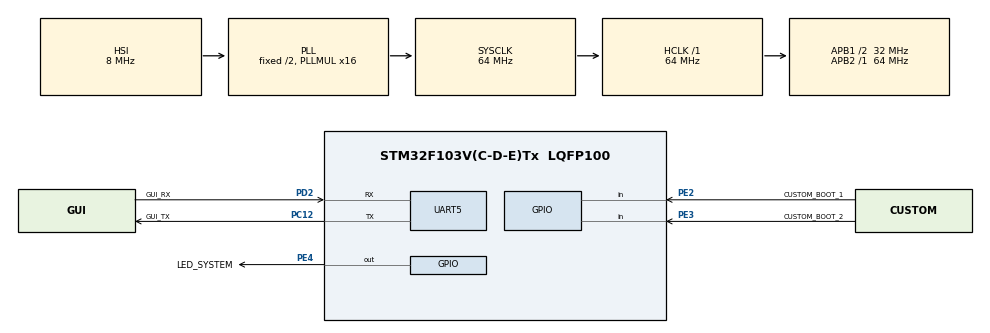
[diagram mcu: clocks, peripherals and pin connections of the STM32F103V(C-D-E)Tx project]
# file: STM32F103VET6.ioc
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Mcu.Family=STM32F1
Mcu.Name=STM32F103V(C-D-E)Tx
Mcu.Package=LQFP100
NVIC.PriorityGroup=NVIC_PRIORITYGROUP_4
NVIC.UART5_IRQn=true\:0\:0\:false\:false\:true\:true\:true\:true
PA13.Mode=JTAG_5_pins
PA13.Signal=SYS_JTMS-SWDIO
PA14.Mode=JTAG_5_pins
PA14.Signal=SYS_JTCK-SWCLK
PA15.Mode=JTAG_5_pins
PA15.Signal=SYS_JTDI
PB3.Mode=JTAG_5_pins
PB3.Signal=SYS_JTDO-TRACESWO
PB4.Mode=JTAG_5_pins
PB4.Signal=SYS_NJTRST
PC12.GPIO_Label=GUI_TX
PC12.Mode=Asynchronous
PC12.Signal=UART5_TX
PD2.GPIO_Label=GUI_RX
PD2.Mode=Asynchronous
PD2.Signal=UART5_RX
PE2.GPIO_Label=CUSTOM_BOOT_1
PE2.Signal=GPIO_Input
PE3.GPIO_Label=CUSTOM_BOOT_2
PE3.Signal=GPIO_Input
PE4.GPIO_Label=LED_SYSTEM
PE4.Signal=GPIO_Output
ProjectManager.HeapSize=0x200
ProjectManager.StackSize=0x400
ProjectManager.TargetToolchain=STM32CubeIDE
RCC.AHBFreq_Value=64000000
RCC.APB1CLKDivider=RCC_HCLK_DIV2
RCC.APB1Freq_Value=32000000
RCC.APB1TimFreq_Value=64000000
RCC.APB2Freq_Value=64000000
RCC.APB2TimFreq_Value=64000000
RCC.HCLKFreq_Value=64000000
RCC.PLLMUL=RCC_PLL_MUL16
RCC.SYSCLKFreq_VALUE=64000000
RCC.SYSCLKSource=RCC_SYSCLKSOURCE_PLLCLK
RCC.USBFreq_Value=64000000
UART5.VirtualMode=Asynchronous
board=custom

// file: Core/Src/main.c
/* USER CODE BEGIN Header */
/**
  ******************************************************************************
  * @file           : main.c
  * @brief          : Main program body
  ******************************************************************************
  * @attention
  *
  * Copyright (c) 2022 STMicroelectronics.
  * All rights reserved.
  *
  * This software is licensed under terms that can be found in the LICENSE file
  * in the root directory of this software component.
  * If no LICENSE file comes with this software, it is provided AS-IS.
  *
  ******************************************************************************
  */
/* USER CODE END Header */
#include "main.h"
#include "usart.h"
#include "gpio.h"

/* USER CODE BEGIN Includes */
#include <stdio.h>

#include "lib_printf.h"
#include "defines.h"
#include "bsp_uart_interrupt.h"

#include "iap.h"
/* USER CODE END Includes */

void SystemClock_Config(void);

int main(void)
{

	/* MCU Configuration--------------------------------------------------------*/

	/* Reset of all peripherals, Initializes the Flash interface and the Systick. */
	HAL_Init();

	/* Configure the system clock */
	SystemClock_Config();

	/* Initialize all configured peripherals */
	MX_GPIO_Init();
	MX_UART5_Init();

	/* USER CODE BEGIN 2 */
	IAP_Init();
	/* USER CODE END 2 */

	/* Infinite loop */
	/* USER CODE BEGIN WHILE */
	while (1)
	{
		IAP_Proc();

		//printf("Hello World \n");
		//HAL_GPIO_TogglePin(LED_SYSTEM_GPIO_Port, LED_SYSTEM_Pin);
		//HAL_Delay(1000);
	/* USER CODE END WHILE */

	}
}

void SystemClock_Config(void)
{
	RCC_OscInitTypeDef RCC_OscInitStruct 	= {0};
	RCC_ClkInitTypeDef RCC_ClkInitStruct 	= {0};

	/** Initializes the RCC Oscillators according to the specified parameters in the RCC_OscInitTypeDef structure.*/
	RCC_OscInitStruct.OscillatorType 		= RCC_OSCILLATORTYPE_HSI;
	RCC_OscInitStruct.HSIState 				= RCC_HSI_ON;
	RCC_OscInitStruct.HSICalibrationValue	= RCC_HSICALIBRATION_DEFAULT;
	RCC_OscInitStruct.PLL.PLLState 			= RCC_PLL_ON;
	RCC_OscInitStruct.PLL.PLLSource 		= RCC_PLLSOURCE_HSI_DIV2;
	RCC_OscInitStruct.PLL.PLLMUL 			= RCC_PLL_MUL16;
	if (HAL_RCC_OscConfig(&RCC_OscInitStruct) != HAL_OK)
	{
		Error_Handler();
	}

	/** Initializes the CPU, AHB and APB buses clocks */
	RCC_ClkInitStruct.ClockType 			= RCC_CLOCKTYPE_HCLK|RCC_CLOCKTYPE_SYSCLK|RCC_CLOCKTYPE_PCLK1|RCC_CLOCKTYPE_PCLK2;
	RCC_ClkInitStruct.SYSCLKSource 			= RCC_SYSCLKSOURCE_PLLCLK;
	RCC_ClkInitStruct.AHBCLKDivider 		= RCC_SYSCLK_DIV1;
	RCC_ClkInitStruct.APB1CLKDivider 		= RCC_HCLK_DIV2;
	RCC_ClkInitStruct.APB2CLKDivider 		= RCC_HCLK_DIV1;
	if (HAL_RCC_ClockConfig(&RCC_ClkInitStruct, FLASH_LATENCY_2) != HAL_OK)
	{
		Error_Handler();
	}
}

void Error_Handler(void)
{
	__disable_irq();
	while (1)
	{
	}
}

#ifdef  USE_FULL_ASSERT
/**
  * @brief  Reports the name of the source file and the source line number
  *         where the assert_param error has occurred.
  * @param  file: pointer to the source file name
  * @param  line: assert_param error line source number
  * @retval None
  */
void assert_failed(uint8_t *file, uint32_t line)
{
	/* USER CODE BEGIN 6 */
	/* User can add his own implementation to report the file name and line number,
		ex: printf("Wrong parameters value: file %s on line %d\r\n", file, line) */
	printf("Wrong parameters value: file %s on line %d\r\n", file, (int)line);
	/* USER CODE END 6 */
}
#endif /* USE_FULL_ASSERT */
